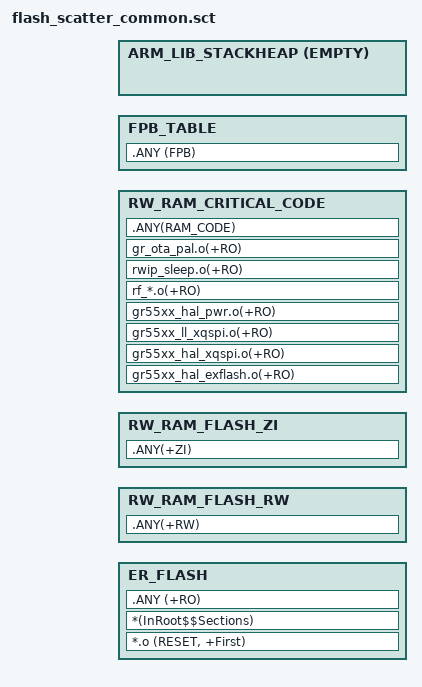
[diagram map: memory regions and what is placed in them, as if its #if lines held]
#! armcc -E -I ..\..\..\..\..\vendors\goodix\GR551x_SDK_V1_00\build\config\ --cpu Cortex-M4.fp
;#! armcc -E -I ..\..\..\..\..\..\..\..\vendors\goodix\GR551x_SDK_V1_00\build\config\ --cpu Cortex-M4
;#! armcc -E -I ..\Src\config\ --cpu Cortex-M4

#include "flash_scatter_config.h"
#define ALIGN_DWORD 0x0008
#define ALIGN_WORD  0x0004
#define ALIGN_16KB  0x4000
#define ALIGN_32KB  0x8000

; *************************************************************
; *** Scatter-Loading Description File generated by uVision ***
; *************************************************************
;
; If an application uses a different memory layout then it must
; use a customized scatter file.
;**************************************************************

LR_FLASH APP_CODE_RUN_ADDR FLASH_SIZE {

    ; Flash layout
    ER_FLASH APP_CODE_RUN_ADDR APP_MAX_CODE_SIZE {  ; load address = execution address
        *.o (RESET, +First)
        *(InRoot$$Sections)
        .ANY (+RO)
      }


    ; RAM Layout
    ; reserved retention RAM for ROM code
    ;RW_RAM_RESERVED_FOR_ROM RAM_START_ADDR EMPTY ROM_RTN_RAM_SIZE {}  

    ; RAM for Application code
    RW_RAM_FLASH_RW (RAM_START_ADDR + ROM_RTN_RAM_SIZE) APP_RAM_SIZE {
        .ANY(+RW)
    }
    RW_RAM_FLASH_ZI +0 APP_RAM_SIZE {
        .ANY(+ZI)
    }

    #if defined(XIP_MODE)
    ; retention RAM for exflash driver code
    RW_RAM_CRITICAL_CODE AlignExpr(+0, ALIGN_WORD) CRITICAL_CODE_MAX_SIZE {
        gr55xx_hal_exflash.o(+RO)
        gr55xx_hal_xqspi.o(+RO)
        gr55xx_ll_xqspi.o(+RO)
        gr55xx_hal_pwr.o(+RO)
        rf_*.o(+RO)
        rwip_sleep.o(+RO)
		gr_ota_pal.o(+RO)
        .ANY(RAM_CODE)
    }
    #endif
    #if defined(RAM_ALIAS)
    FPB_TABLE  AlignExpr(+0X2F800000, 32)   {
        .ANY (FPB)
    }
    #else
    FPB_TABLE  AlignExpr(+0, 32)   {
        .ANY (FPB)
    }
    #endif

    ; define call-stack space
    ARM_LIB_STACKHEAP AlignExpr(STACK_END_ADDR, ALIGN_DWORD) EMPTY -CSTACK_HEAP_SIZE {}
}
